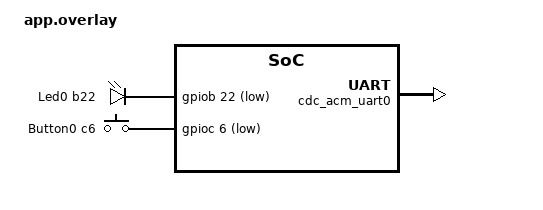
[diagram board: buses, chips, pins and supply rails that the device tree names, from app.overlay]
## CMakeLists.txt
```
# SPDX-License-Identifier: Apache-2.0

cmake_minimum_required(VERSION 3.20.0)


set(BOARD_ROOT ${CMAKE_SOURCE_DIR}/..)
set(BOARD fmuk64f)


find_package(Zephyr REQUIRED HINTS $ENV{ZEPHYR_BASE})
project(button)

target_sources(app PRIVATE 
		src/main.c
		src/m_button.c
		src/m_console.c
		src/m_timer.c
		)

target_include_directories(app PUBLIC ${CMAKE_CURRENT_SOURCE_DIR}/src)
```

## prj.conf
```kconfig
CONFIG_GPIO=y




CONFIG_SERIAL=y
CONFIG_CONSOLE=y
CONFIG_UART_CONSOLE=y
CONFIG_STDOUT_CONSOLE=y
CONFIG_UART_LINE_CTRL=y
CONFIG_USB_DEVICE_STACK_NEXT=y
CONFIG_CDC_ACM_SERIAL_INITIALIZE_AT_BOOT=y
CONFIG_CDC_ACM_SERIAL_PID=0x0004
CONFIG_CDC_ACM_SERIAL_PRODUCT_STRING="USBD console"
```

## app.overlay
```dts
/* app.overlay */

/ {
    chosen {
        zephyr,console = &cdc_acm_uart0;
    };

    aliases {
        myled0 = &user_led0;
        mysw0 = &user_button0;
    };

    overlay_leds {        
        compatible = "gpio-leds";

        user_led0: led_0 {
            label = "Led0 b22";
            gpios = <&gpiob 22 GPIO_ACTIVE_LOW>;
        };
    };

    overlay_gpio_keys {
        compatible = "gpio-keys";   
    /*    deboune-interval-ms = <50>;   */
    /*    polling-mode;                 */

        user_button0: button_0 {
            label = "Button0 c6";
            gpios = <&gpioc 6 (GPIO_ACTIVE_LOW | GPIO_PULL_UP)>;
        };
    };
};

&zephyr_udc0 {
    cdc_acm_uart0: cdc_acm_uart0 {
        compatible = "zephyr,cdc-acm-uart";
    };
};

/** fmuk64f.dts ***
zephyr_udc0: &usbotg {
    compatible = "nxp,kinetis-usbd";
    status = "okay";
    num-bidir-endpoints = <8>;
};
**/
```

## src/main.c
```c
#include <stdio.h>
//#include <inttypes.h>
#include <zephyr/kernel.h>
//#include <zephyr/device.h>
//#include <zephyr/sys/util.h>
#include <zephyr/sys/printk.h>
#include "m_console.h"
#include "m_button.h"
#include "m_timer.h"

#define MYTIME_1000MS	1000



void timer_work_handler(struct k_work *item)
{
	struct m_timer_info *drv = 
		CONTAINER_OF(item, struct m_timer_info, work);
	k_mutex_lock(&drv->mutex, K_FOREVER);
	printk("timer_handler()\n");
	k_mutex_unlock(&drv->mutex);
}

void button_handler(void)
{
	printk("button_handler()\n");
	m_led_toggle();
}


int main(void)
{
	struct m_timer_info mytimer = {
		.handler = timer_work_handler,
		.duration = K_SECONDS(1),
		.period = K_SECONDS(1) };

	m_console_init();
	printk("main() start\n");

	m_button_init(button_handler);
	m_led_init();

	m_timer_init(&mytimer);
	
	while(1){
		k_msleep(MYTIME_1000MS);
	}
	return 0;
}
```

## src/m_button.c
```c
/*
 * Copyright (c) 2016 Open-RnD Sp. z o.o.
 * Copyright (c) 2020 Nordic Semiconductor ASA
 *
 * SPDX-License-Identifier: Apache-2.0
 *
 * NOTE: If you are looking into an implementation of button events with
 * debouncing, check out `input` subsystem and `samples/subsys/input/input_dump`
 * example instead.
 */


#include "m_button.h"
#include <zephyr/device.h>
#include <zephyr/drivers/gpio.h>

// #include <zephyr/sys/printk.h>
#include <inttypes.h>
#include <errno.h>
#include <zephyr/logging/log.h>
LOG_MODULE_REGISTER(m_button);



static struct gpio_dt_spec s_btn = GPIO_DT_SPEC_GET_OR(SW0_NODE, gpios, {0});

static struct gpio_dt_spec s_led = GPIO_DT_SPEC_GET_OR(LED0_NODE, gpios, {0});

static struct gpio_callback button_handler;

void (*s_handler)(void);

/**************************
 * cbutton pressed callback 
 * */
void s_button_pressed(const struct device *dev, struct gpio_callback *cb, uint32_t pins)
{
	LOG_DBG("Button pressed at %" PRIu32 "\n", k_cycle_get_32());
	
	/* do something */
	s_handler();
	
	// /* If we have an LED, match its state to the button's. */
	// if (s_led.port) {		
	// 	int val = gpio_pin_get_dt(&s_btn);
	// 	if (val >= 0) { 
	// 		gpio_pin_set_dt(&s_led, val);
	// 	}
	// }
}


int m_button_init(void(*handler)(void))
{
	int ret;
	s_handler = handler; 

	if (!gpio_is_ready_dt(&s_btn)) {
		LOG_DBG("Error: button device %s is not ready\n", s_btn.port->name);
		return -ENODEV;
	}

	ret = gpio_pin_configure_dt(&s_btn, GPIO_INPUT);
	if (ret != 0) {
		LOG_DBG("Error %d: failed to configure %s pin %d\n",
		       ret, s_btn.port->name, s_btn.pin);
		return -ENODEV;
	}

	ret = gpio_pin_interrupt_configure_dt(&s_btn, GPIO_INT_EDGE_TO_ACTIVE);
	if (ret != 0) {
		LOG_DBG("Error %d: failed to configure interrupt on %s pin %d\n",
			ret, s_btn.port->name, s_btn.pin);
		return -EINTR;
	}

	gpio_init_callback(&button_handler, s_button_pressed, BIT(s_btn.pin));
	gpio_add_callback(s_btn.port, &button_handler);
	LOG_DBG("Set up button at %s pin %d\n", s_btn.port->name, s_btn.pin);	

	return 0;
}

int m_led_init(void)
{
	int ret;
	if (s_led.port && !gpio_is_ready_dt(&s_led)) {
		LOG_DBG("Error: LED device %s is not ready; ignoring it\n", s_led.port->name);
		s_led.port = NULL;
		return -ENODEV;
	}
	if (s_led.port) {
		ret = gpio_pin_configure_dt(&s_led, GPIO_OUTPUT);
		if (ret != 0) {
			LOG_DBG("Error %d: failed to configure LED device %s pin %d\n",
			       ret, s_led.port->name, s_led.pin);
			s_led.port = NULL;
			return -ENODEV;
		} else {
			LOG_DBG("Set up LED at %s pin %d\n", s_led.port->name, s_led.pin);
		}
	}
	return 0;
}

int m_led_set(int val)
{
	int ret;
	LOG_DBG("Set LED to %d\n", val);
	ret = gpio_pin_set_dt(&s_led, val);
	return 0;
}

int m_led_toggle(void)
{
	int ret;
	LOG_DBG("Set LED toggle\n");
	ret = gpio_pin_toggle_dt(&s_led);
	return 0;

}
```

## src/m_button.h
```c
#ifndef _M_BUTTON_H_
#define _M_BUTTON_H_

#include <stdio.h>
#include <zephyr/kernel.h>
#include <zephyr/sys/util.h>


/*
 * Get button configuration from the devicetree sw0 alias. This is mandatory.
 */
#define SW0_NODE	DT_ALIAS(mysw0)
#if !DT_NODE_HAS_STATUS_OKAY(SW0_NODE)
#error "Unsupported board: sw0 devicetree alias is not defined"
#endif
/*
 * The led0 devicetree alias is optional. If present, we'll use it
 * to turn on the LED whenever the button is pressed.
 */
#define LED0_NODE	DT_ALIAS(myled0)
#if !DT_NODE_HAS_STATUS_OKAY(LED0_NODE)
#error "Unsupported board: led0 devicetree alias is not defined"
#endif



int m_button_init(void(*handler)(void));

int m_led_init(void);

int m_led_set(int val);

int m_led_toggle(void);

#endif /* M_BUTTON_H_ */
```

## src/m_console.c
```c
#include "m_console.h"
#include <zephyr/drivers/uart.h>
#include <zephyr/sys/printk.h>
#include <zephyr/logging/log.h>

LOG_MODULE_REGISTER(m_console);



const struct device *const dev = DEVICE_DT_GET(CONSOLE_MODE);

int m_console_init(void)
{
	uint32_t dtr = 0;
	LOG_DBG("m_console_init()\n");

	/* Poll if the DTR flag was set */
	while (!dtr) {
		uart_line_ctrl_get(dev, UART_LINE_CTRL_DTR, &dtr);
		/* Give CPU resources to low priority threads. */
		k_sleep(K_MSEC(100));
	}

	printk("console is ready\n");

	return 0;
}
```

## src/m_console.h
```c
#ifndef _M_CONSOLE_H_
#define _M_CONSOLE_H_


#include <stdio.h>
#include <zephyr/kernel.h>
#include <zephyr/sys/util.h>

#define CONSOLE_MODE	DT_CHOSEN(zephyr_console)
BUILD_ASSERT(DT_NODE_HAS_COMPAT(CONSOLE_MODE, zephyr_cdc_acm_uart),
	"Console device is not ACM CDC UART");


int m_console_init(void);

#endif /* _M_CONSPLE_H_ */
```

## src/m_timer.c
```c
#include "m_timer.h"

#include <zephyr/device.h>
#include <errno.h>
#include <zephyr/logging/log.h>
LOG_MODULE_REGISTER(m_timer);



void s_timer_handler(struct k_timer *item)
{    
    struct m_timer_info *drv = 
                CONTAINER_OF(item, struct m_timer_info, timer);
    // add to system workqueue
    k_work_submit(&drv->work);    
}

/** public function */
void m_timer_init(struct m_timer_info *timer)
{
    LOG_DBG("m_timer_init()\n");

    k_mutex_init(&timer->mutex);
    k_work_init(&timer->work, timer->handler);
    k_timer_init(&timer->timer, s_timer_handler, NULL);
    // start timer
    k_timer_start(&timer->timer, timer->duration, timer->period);
}
```

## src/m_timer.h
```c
#ifndef _M_TIMER_H_
#define _M_TIMER_H_


#include <stdio.h>
#include <zephyr/kernel.h>
/// container_of()
#include <zephyr/sys/util.h>



struct m_timer_info {
    struct k_work work; 
    struct k_mutex mutex;
    struct k_timer timer;    
    /* user define below */
    void (*handler)(struct k_work*);
    k_timeout_t duration;
    k_timeout_t period;
};

/** main() code example *******************
static void work_handler(struct k_work *item)
{
	struct m_timer_info *drv = 
			CONTAINER_OF(item, struct m_timer_info, work);
	k_mutex_lock(&drv->mutex, K_FOREVER);
    // do something //
    k_mutex_unlock(&drv->mutex);
}
struct m_timer_info timer = {
	.handler = work_handler,
	.duration = K_SECOND(1),
	.period = K_SECOND(1),
}
m_timer_init(&timer);
******************************************/

void m_timer_init(struct m_timer_info *timer);



#endif /* _M_TIMER_H_ */
```
